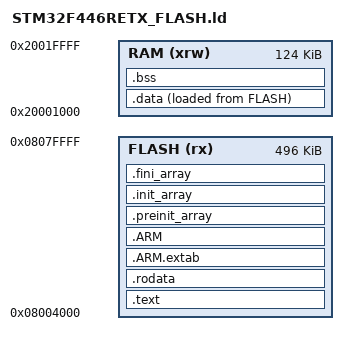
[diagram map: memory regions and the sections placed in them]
ENTRY(run_tests)

MEMORY
{
  RAM     (xrw)    : ORIGIN = 0x20001000,   LENGTH = 128K - 4K
  FLASH    (rx)    : ORIGIN = 0x08004000,   LENGTH = 512K - 16K
}

SECTIONS
{
  .text :
  {
    . = ALIGN(4);
    *(.opentestloader_struct) /* Structure containing addresses and information used for scheduling the test */
    *(.text)                  /* .text sections (code) */
    *(.text*)                 /* .text* sections (code) */
    *(.glue_7)                /* glue arm to thumb code */
    *(.glue_7t)               /* glue thumb to arm code */
    *(.eh_frame)

    KEEP (*(.init))
    KEEP (*(.fini))

    . = ALIGN(4);
    __end_of_text__ = .;      /* define a global symbols at end of code */
  } >FLASH = 0xFF

  .rodata :
  {
    . = ALIGN(4);
    *(.rodata)         /* .rodata sections (constants, strings, etc.) */
    *(.rodata*)        /* .rodata* sections (constants, strings, etc.) */
    . = ALIGN(4);
  } >FLASH = 0xFF

  .ARM.extab   : {
    . = ALIGN(4);
    *(.ARM.extab* .gnu.linkonce.armextab.*)
    . = ALIGN(4);
  } >FLASH = 0xFF

  .ARM : {
    . = ALIGN(4);
    __exidx_start = .;
    *(.ARM.exidx*)
    __exidx_end = .;
    . = ALIGN(4);
  } >FLASH = 0xFF

  .preinit_array     :
  {
    . = ALIGN(4);
    PROVIDE_HIDDEN (__preinit_array_start = .);
    KEEP (*(.preinit_array*))
    PROVIDE_HIDDEN (__preinit_array_end = .);
    . = ALIGN(4);
  } >FLASH = 0xFF

  .init_array :
  {
    . = ALIGN(4);
    PROVIDE_HIDDEN (__init_array_start = .);
    KEEP (*(SORT(.init_array.*)))
    KEEP (*(.init_array*))
    PROVIDE_HIDDEN (__init_array_end = .);
    . = ALIGN(4);
  } >FLASH = 0xFF

  .fini_array :
  {
    . = ALIGN(4);
    PROVIDE_HIDDEN (__fini_array_start = .);
    KEEP (*(SORT(.fini_array.*)))
    KEEP (*(.fini_array*))
    PROVIDE_HIDDEN (__fini_array_end = .);
    . = ALIGN(4);
  } >FLASH = 0xFF

  /* Used by the startup to initialize data */
  __init_data_start__ = LOADADDR(.data);

  /* Initialized data sections into "RAM" Ram type memory */
  .data :
  {
    . = ALIGN(4);
    __data_start__ = .;        /* create a global symbol at data start */
    *(.data)           /* .data sections */
    *(.data*)          /* .data* sections */
    *(.RamFunc)        /* .RamFunc sections */
    *(.RamFunc*)       /* .RamFunc* sections */

    . = ALIGN(4);
    __data_end__ = .;        /* define a global symbol at data end */

  } >RAM AT> FLASH = 0xFF

  /* Uninitialized data section into "RAM" Ram type memory */
  . = ALIGN(4);
  .bss :
  {
    /* This is used by the startup in order to initialize the .bss section */
    _sbss = .;         /* define a global symbol at bss start */
    __bss_start__ = _sbss;
    *(.bss)
    *(.bss*)
    *(COMMON)

    . = ALIGN(4);
    _ebss = .;         /* define a global symbol at bss end */
    __bss_end__ = _ebss;
  } >RAM

  /* Remove information from the compiler libraries */
  /DISCARD/ :
  {
    libc.a ( * )
    libm.a ( * )
    libgcc.a ( * )
  }

  .ARM.attributes 0 : { *(.ARM.attributes) }
}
